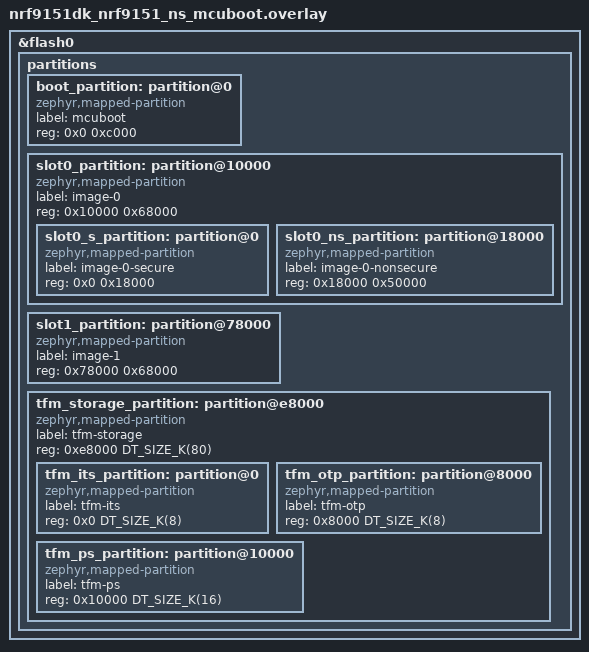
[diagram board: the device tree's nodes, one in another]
/*
 * Copyright (c) 2026 Nordic Semiconductor ASA
 *
 * SPDX-License-Identifier: LicenseRef-Nordic-5-Clause
 */

&flash0 {
	/delete-node/ partitions;

	partitions {
		ranges;
		#address-cells = <1>;
		#size-cells = <1>;

		boot_partition: partition@0 {
			compatible = "zephyr,mapped-partition";
			label = "mcuboot";
			reg = <0x0 0xc000>;
		};

		slot0_partition: partition@10000 {
			compatible = "zephyr,mapped-partition";
			label = "image-0";
			reg = <0x10000 0x68000>;
			ranges = <0x0 0x10000 0x68000>;
			#address-cells = <1>;
			#size-cells = <1>;

			slot0_s_partition: partition@0 {
				compatible = "zephyr,mapped-partition";
				label = "image-0-secure";
				reg = <0x0 0x18000>;
			};

			slot0_ns_partition: partition@18000 {
				compatible = "zephyr,mapped-partition";
				label = "image-0-nonsecure";
				reg = <0x18000 0x50000>;
			};
		};

		slot1_partition: partition@78000 {
			compatible = "zephyr,mapped-partition";
			label = "image-1";
			reg = <0x78000 0x68000>;
		};

		tfm_storage_partition: partition@e8000 {
			compatible = "zephyr,mapped-partition";
			label = "tfm-storage";
			reg = <0xe8000 DT_SIZE_K(80)>;
			ranges = <0x0 0xe8000 DT_SIZE_K(80)>;
			#address-cells = <1>;
			#size-cells = <1>;

			tfm_its_partition: partition@0 {
				compatible = "zephyr,mapped-partition";
				label = "tfm-its";
				reg = <0x0 DT_SIZE_K(8)>;
			};

			tfm_otp_partition: partition@8000 {
				compatible = "zephyr,mapped-partition";
				label = "tfm-otp";
				reg = <0x8000 DT_SIZE_K(8)>;
			};

			tfm_ps_partition: partition@10000 {
				compatible = "zephyr,mapped-partition";
				label = "tfm-ps";
				reg = <0x10000 DT_SIZE_K(16)>;
			};
		};
	};
};
